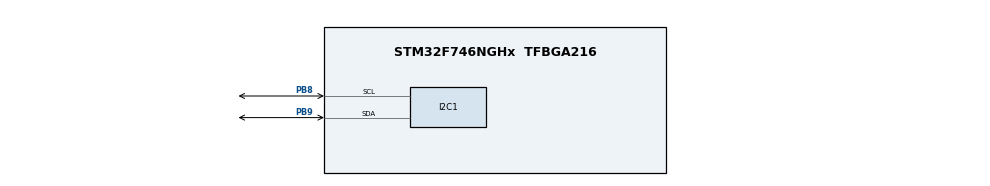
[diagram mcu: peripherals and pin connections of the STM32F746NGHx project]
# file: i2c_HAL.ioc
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Mcu.Family=STM32F7
Mcu.Name=STM32F746NGHx
Mcu.Package=TFBGA216
NVIC.PriorityGroup=NVIC_PRIORITYGROUP_4
PB8.Mode=I2C
PB8.Signal=I2C1_SCL
PB9.Mode=I2C
PB9.Signal=I2C1_SDA
ProjectManager.HeapSize=0x200
ProjectManager.StackSize=0x400
ProjectManager.TargetToolchain=STM32CubeIDE
RCC.HSE_VALUE=25000000
RCC.HSI_VALUE=16000000
RCC.LSE_VALUE=32768
RCC.USBFreq_Value=96000000
RCC.VCOOutputFreq_Value=192000000
board=custom

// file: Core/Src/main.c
/* USER CODE BEGIN Header */
/**
  ******************************************************************************
  * @file           : main.c
  * @brief          : Main program body
  ******************************************************************************
  * @attention
  *
  * <h2><center>&copy; Copyright (c) 2021 STMicroelectronics.
  * All rights reserved.</center></h2>
  *
  * This software component is licensed by ST under BSD 3-Clause license,
  * the "License"; You may not use this file except in compliance with the
  * License. You may obtain a copy of the License at:
  *                        opensource.org/licenses/BSD-3-Clause
  *
  ******************************************************************************
  */
/* USER CODE END Header */
#include "main.h"
#include "ssd1306_tests.h"
#include "ssd1306.h"

/* USER CODE BEGIN PM */
#define app 15
/* USER CODE END PM */

I2C_HandleTypeDef hi2c1;

void SystemClock_Config(void);
static void MX_GPIO_Init(void);
static void MX_I2C1_Init(void);

int main(void)
{

  /* MCU Configuration--------------------------------------------------------*/

  /* Reset of all peripherals, Initializes the Flash interface and the Systick. */
  HAL_Init();

  /* Configure the system clock */
  SystemClock_Config();

  /* Initialize all configured peripherals */
  MX_GPIO_Init();
  MX_I2C1_Init();
  /* USER CODE BEGIN 2 */
  ssd1306_Init();
  /* USER CODE END 2 */
 // ssd1306_TestAll();
  /* Infinite loop */
  while (1)
  {
	  for(int i = 0; i < app ; i++){

	  ssd1306_SetCursor(i, 5);
	  ssd1306_WriteString("D U B B", Font_16x26, White);
	  ssd1306_UpdateScreen();
	  HAL_Delay(1);
	  ssd1306_Fill(Black);
	  }
	  for(int i = app; i > 0 ; i--){

	 	  ssd1306_SetCursor(i, 5);
	 	  ssd1306_WriteString("D U B B", Font_16x26, White);
	 	  ssd1306_UpdateScreen();
	 	  HAL_Delay(1);
	 	  ssd1306_Fill(Black);
	 	  }
  /* USER CODE END 3 */
}
}
void SystemClock_Config(void)
{
  RCC_OscInitTypeDef RCC_OscInitStruct = {0};
  RCC_ClkInitTypeDef RCC_ClkInitStruct = {0};
  RCC_PeriphCLKInitTypeDef PeriphClkInitStruct = {0};

  /** Configure the main internal regulator output voltage
  */
  __HAL_RCC_PWR_CLK_ENABLE();
  __HAL_PWR_VOLTAGESCALING_CONFIG(PWR_REGULATOR_VOLTAGE_SCALE3);
  /** Initializes the RCC Oscillators according to the specified parameters
  * in the RCC_OscInitTypeDef structure.
  */
  RCC_OscInitStruct.OscillatorType = RCC_OSCILLATORTYPE_HSI;
  RCC_OscInitStruct.HSIState = RCC_HSI_ON;
  RCC_OscInitStruct.HSICalibrationValue = RCC_HSICALIBRATION_DEFAULT;
  RCC_OscInitStruct.PLL.PLLState = RCC_PLL_NONE;
  if (HAL_RCC_OscConfig(&RCC_OscInitStruct) != HAL_OK)
  {
    Error_Handler();
  }
  /** Initializes the CPU, AHB and APB buses clocks
  */
  RCC_ClkInitStruct.ClockType = RCC_CLOCKTYPE_HCLK|RCC_CLOCKTYPE_SYSCLK
                              |RCC_CLOCKTYPE_PCLK1|RCC_CLOCKTYPE_PCLK2;
  RCC_ClkInitStruct.SYSCLKSource = RCC_SYSCLKSOURCE_HSI;
  RCC_ClkInitStruct.AHBCLKDivider = RCC_SYSCLK_DIV1;
  RCC_ClkInitStruct.APB1CLKDivider = RCC_HCLK_DIV1;
  RCC_ClkInitStruct.APB2CLKDivider = RCC_HCLK_DIV1;

  if (HAL_RCC_ClockConfig(&RCC_ClkInitStruct, FLASH_LATENCY_0) != HAL_OK)
  {
    Error_Handler();
  }
  PeriphClkInitStruct.PeriphClockSelection = RCC_PERIPHCLK_I2C1;
  PeriphClkInitStruct.I2c1ClockSelection = RCC_I2C1CLKSOURCE_PCLK1;
  if (HAL_RCCEx_PeriphCLKConfig(&PeriphClkInitStruct) != HAL_OK)
  {
    Error_Handler();
  }
}

static void MX_I2C1_Init(void)
{

  hi2c1.Instance = I2C1;
  hi2c1.Init.Timing = 0x00303D5B;
  hi2c1.Init.OwnAddress1 = 0;
  hi2c1.Init.AddressingMode = I2C_ADDRESSINGMODE_7BIT;
  hi2c1.Init.DualAddressMode = I2C_DUALADDRESS_DISABLE;
  hi2c1.Init.OwnAddress2 = 0;
  hi2c1.Init.OwnAddress2Masks = I2C_OA2_NOMASK;
  hi2c1.Init.GeneralCallMode = I2C_GENERALCALL_DISABLE;
  hi2c1.Init.NoStretchMode = I2C_NOSTRETCH_DISABLE;
  if (HAL_I2C_Init(&hi2c1) != HAL_OK)
  {
    Error_Handler();
  }
  /** Configure Analogue filter
  */
  if (HAL_I2CEx_ConfigAnalogFilter(&hi2c1, I2C_ANALOGFILTER_ENABLE) != HAL_OK)
  {
    Error_Handler();
  }
  /** Configure Digital filter
  */
  if (HAL_I2CEx_ConfigDigitalFilter(&hi2c1, 0) != HAL_OK)
  {
    Error_Handler();
  }

}

static void MX_GPIO_Init(void)
{

  /* GPIO Ports Clock Enable */
  __HAL_RCC_GPIOB_CLK_ENABLE();

}

void Error_Handler(void)
{
}

/************************ (C) COPYRIGHT STMicroelectronics *****END OF FILE****/
